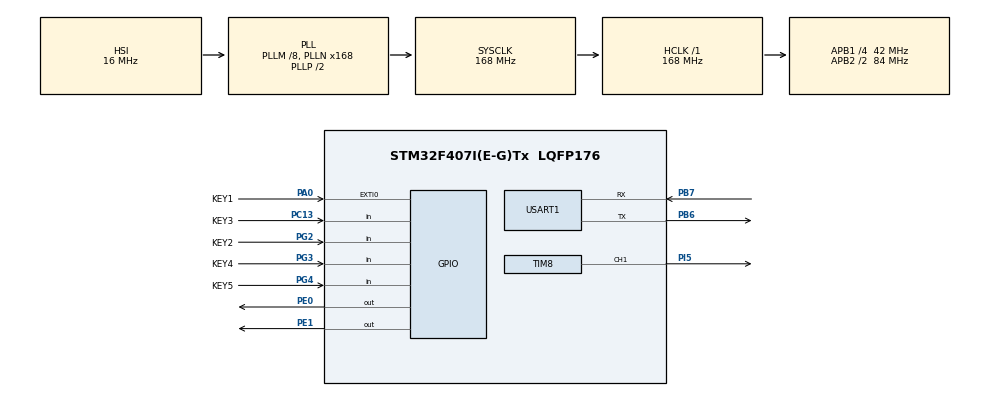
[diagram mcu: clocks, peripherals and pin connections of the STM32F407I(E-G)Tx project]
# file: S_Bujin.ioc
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Mcu.Family=STM32F4
Mcu.Name=STM32F407I(E-G)Tx
Mcu.Package=LQFP176
NVIC.PriorityGroup=NVIC_PRIORITYGROUP_4
NVIC.TIM8_CC_IRQn=true\:0\:0\:false\:false\:true\:true\:true\:true
PA0-WKUP.GPIO_Label=KEY1
PA0-WKUP.Signal=GPXTI0
PA13.Mode=Serial_Wire
PA13.Signal=SYS_JTMS-SWDIO
PA14.Mode=Serial_Wire
PA14.Signal=SYS_JTCK-SWCLK
PB6.Mode=Asynchronous
PB6.Signal=USART1_TX
PB7.Mode=Asynchronous
PB7.Signal=USART1_RX
PC13-ANTI_TAMP.GPIO_Label=KEY3
PC13-ANTI_TAMP.Signal=GPIO_Input
PE0.Signal=GPIO_Output
PE1.Signal=GPIO_Output
PG2.GPIO_Label=KEY2
PG2.Signal=GPIO_Input
PG3.GPIO_Label=KEY4
PG3.Signal=GPIO_Input
PG4.GPIO_Label=KEY5
PG4.Signal=GPIO_Input
PH0-OSC_IN.Mode=HSE-External-Oscillator
PH0-OSC_IN.Signal=RCC_OSC_IN
PH1-OSC_OUT.Mode=HSE-External-Oscillator
PH1-OSC_OUT.Signal=RCC_OSC_OUT
PI5.Signal=S_TIM8_CH1
ProjectManager.HeapSize=0x200
ProjectManager.StackSize=0x400
ProjectManager.TargetToolchain=MDK-ARM V5.32
RCC.48MHZClocksFreq_Value=84000000
RCC.AHBFreq_Value=168000000
RCC.APB1CLKDivider=RCC_HCLK_DIV4
RCC.APB1Freq_Value=42000000
RCC.APB1TimFreq_Value=84000000
RCC.APB2CLKDivider=RCC_HCLK_DIV2
RCC.APB2Freq_Value=84000000
RCC.APB2TimFreq_Value=168000000
RCC.CortexFreq_Value=168000000
RCC.HCLKFreq_Value=168000000
RCC.HSE_VALUE=25000000
RCC.HSI_VALUE=16000000
RCC.LSE_VALUE=32768
RCC.PLLM=8
RCC.PLLN=168
RCC.SYSCLKFreq_VALUE=168000000
RCC.SYSCLKSource=RCC_SYSCLKSOURCE_PLLCLK
RCC.VCOOutputFreq_Value=336000000
SH.S_TIM8_CH1.0=TIM8_CH1,Output Compare1 CH1
TIM8.Channel-Output\ Compare1\ CH1=TIM_CHANNEL_1
USART1.VirtualMode=VM_ASYNC
board=custom

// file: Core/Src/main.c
/* USER CODE BEGIN Header */
/**
  ******************************************************************************
  * @file           : main.c
  * @brief          : Main program body
  ******************************************************************************
  * @attention
  *
  * Copyright (c) 2023 STMicroelectronics.
  * All rights reserved.
  *
  * This software is licensed under terms that can be found in the LICENSE file
  * in the root directory of this software component.
  * If no LICENSE file comes with this software, it is provided AS-IS.
  *
  ******************************************************************************
  */
/* USER CODE END Header */
#include "main.h"
#include "tim.h"
#include "usart.h"
#include "gpio.h"

/* USER CODE BEGIN Includes */
#include "S_Speed.h"
#include "stdio.h"

/* USER CODE END Includes */

void SystemClock_Config(void);

/* USER CODE BEGIN 0 */
extern Stepper_Typedef Stepper;

/* USER CODE END 0 */

int main(void)
{

  /* MCU Configuration--------------------------------------------------------*/

  /* Reset of all peripherals, Initializes the Flash interface and the Systick. */
  HAL_Init();

  /* Configure the system clock */
  SystemClock_Config();

  /* Initialize all configured peripherals */
  MX_GPIO_Init();
  MX_TIM8_Init();
  MX_USART1_UART_Init();
  /* USER CODE BEGIN 2 */
	print_flag=1;
  /* USER CODE END 2 */

  /* Infinite loop */
  while (1)
  {

    /* USER CODE BEGIN 3 */
	  if(Key_Scan(KEY2_GPIO_Port,KEY2_Pin) == KEY_ON)
	{
		if(print_flag)
		{
			/*步进电机加速部分*/
			stepper_move_S(1,100,0.1f);
			print_flag=0;
		}

	}
	if( Stepper.status == AVESPEED)
		{
			/*步进电机减速部分*/
			stepper_move_S(100,1,0.1f);
			Stepper.status = DECEL;
		}

  }
  /* USER CODE END 3 */
}

void SystemClock_Config(void)
{
  RCC_OscInitTypeDef RCC_OscInitStruct = {0};
  RCC_ClkInitTypeDef RCC_ClkInitStruct = {0};

  /** Configure the main internal regulator output voltage
  */
  __HAL_RCC_PWR_CLK_ENABLE();
  __HAL_PWR_VOLTAGESCALING_CONFIG(PWR_REGULATOR_VOLTAGE_SCALE1);

  /** Initializes the RCC Oscillators according to the specified parameters
  * in the RCC_OscInitTypeDef structure.
  */
  RCC_OscInitStruct.OscillatorType = RCC_OSCILLATORTYPE_HSI;
  RCC_OscInitStruct.HSIState = RCC_HSI_ON;
  RCC_OscInitStruct.HSICalibrationValue = RCC_HSICALIBRATION_DEFAULT;
  RCC_OscInitStruct.PLL.PLLState = RCC_PLL_ON;
  RCC_OscInitStruct.PLL.PLLSource = RCC_PLLSOURCE_HSI;
  RCC_OscInitStruct.PLL.PLLM = 8;
  RCC_OscInitStruct.PLL.PLLN = 168;
  RCC_OscInitStruct.PLL.PLLP = RCC_PLLP_DIV2;
  RCC_OscInitStruct.PLL.PLLQ = 4;
  if (HAL_RCC_OscConfig(&RCC_OscInitStruct) != HAL_OK)
  {
    Error_Handler();
  }

  /** Initializes the CPU, AHB and APB buses clocks
  */
  RCC_ClkInitStruct.ClockType = RCC_CLOCKTYPE_HCLK|RCC_CLOCKTYPE_SYSCLK
                              |RCC_CLOCKTYPE_PCLK1|RCC_CLOCKTYPE_PCLK2;
  RCC_ClkInitStruct.SYSCLKSource = RCC_SYSCLKSOURCE_PLLCLK;
  RCC_ClkInitStruct.AHBCLKDivider = RCC_SYSCLK_DIV1;
  RCC_ClkInitStruct.APB1CLKDivider = RCC_HCLK_DIV4;
  RCC_ClkInitStruct.APB2CLKDivider = RCC_HCLK_DIV2;

  if (HAL_RCC_ClockConfig(&RCC_ClkInitStruct, FLASH_LATENCY_5) != HAL_OK)
  {
    Error_Handler();
  }
  if (HAL_GetREVID() == 0x1001)
  {
    /* Enable the Flash prefetch */
    __HAL_FLASH_PREFETCH_BUFFER_ENABLE();
  }
}

void Error_Handler(void)
{
  __disable_irq();
  while (1)
  {
  }
}
